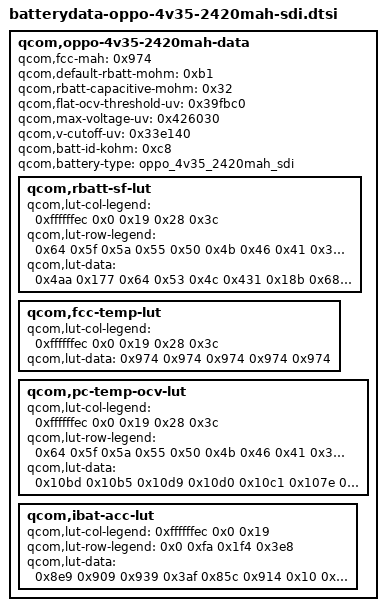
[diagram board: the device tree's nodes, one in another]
/* Copyright (c) 2020, The Linux Foundation. All rights reserved.
*  Copyright (c) 2020, the_shahnawaz_sheikh (sheikhshahnawaz41299).
*
* This program is free software; you can redistribute it and/or modify
* it under the terms of the GNU General Public License version 2 and
* only version 2 as published by the Free Software Foundation.
*
* This program is distributed in the hope that it will be useful,
* but WITHOUT ANY WARRANTY; without even the implied warranty of
* MERCHANTABILITY or FITNESS FOR A PARTICULAR PURPOSE.  See the
* GNU General Public License for more details.
*/

		qcom,oppo-4v35-2420mah-data {
			qcom,fcc-mah = <0x974>;
			qcom,default-rbatt-mohm = <0xb1>;
			qcom,rbatt-capacitive-mohm = <0x32>;
			qcom,flat-ocv-threshold-uv = <0x39fbc0>;
			qcom,max-voltage-uv = <0x426030>;
			qcom,v-cutoff-uv = <0x33e140>;
			qcom,batt-id-kohm = <0xc8>;
			qcom,battery-type = "oppo_4v35_2420mah_sdi";

			qcom,rbatt-sf-lut {
				qcom,lut-col-legend = <0xffffffec 0x0 0x19 0x28 0x3c>;
				qcom,lut-row-legend = <0x64 0x5f 0x5a 0x55 0x50 0x4b 0x46 0x41 0x3c 0x37 0x32 0x2d 0x28 0x23 0x1e 0x19 0x14 0x10 0xd 0xb 0xa 0x9 0x8 0x7 0x6 0x5 0x4 0x3 0x2 0x1 0x0>;
				qcom,lut-data = <0x4aa 0x177 0x64 0x53 0x4c 0x431 0x18b 0x68 0x56 0x4e 0x3df 0x172 0x6a 0x53 0x4c 0x3ac 0x172 0x6c 0x55 0x50 0x38d 0x15c 0x65 0x57 0x50 0x355 0x155 0x6e 0x5e 0x52 0x346 0x14d 0x6b 0x5c 0x59 0x346 0x139 0x73 0x63 0x5c 0x344 0x125 0x6a 0x52 0x4f 0x346 0x124 0x62 0x4e 0x4c 0x34f 0x139 0x63 0x55 0x50 0x363 0x124 0x60 0x53 0x50 0x373 0x123 0x60 0x59 0x52 0x38b 0x136 0x63 0x5a 0x53 0x3b0 0x14d 0x62 0x56 0x52 0x3de 0x155 0x63 0x53 0x4f 0x416 0x162 0x66 0x57 0x4f 0x439 0x180 0x69 0x53 0x50 0x46f 0x18f 0x6c 0x55 0x50 0x48b 0x1a1 0x65 0x57 0x53 0x4a2 0x1b2 0x63 0x56 0x50 0x4b4 0x1b7 0x64 0x59 0x50 0x4dd 0x1d4 0x65 0x59 0x56 0x4f4 0x1cc 0x69 0x5c 0x53 0x511 0x1ee 0x6b 0x59 0x52 0x526 0x1e2 0x6c 0x59 0x55 0x541 0x1f0 0x6f 0x59 0x57 0x55b 0x1f6 0x72 0x5c 0x5a 0x59b 0x218 0x77 0x74 0x6e 0x69d 0x261 0xb6 0x2c4 0x1d0 0x7b7 0x333 0x14b 0x338 0x226>;
			};

			qcom,fcc-temp-lut {
				qcom,lut-col-legend = <0xffffffec 0x0 0x19 0x28 0x3c>;
				qcom,lut-data = <0x974 0x974 0x974 0x974 0x974>;
			};

			qcom,pc-temp-ocv-lut {
				qcom,lut-col-legend = <0xffffffec 0x0 0x19 0x28 0x3c>;
				qcom,lut-row-legend = <0x64 0x5f 0x5a 0x55 0x50 0x4b 0x46 0x41 0x3c 0x37 0x32 0x2d 0x28 0x23 0x1e 0x19 0x14 0x10 0xd 0xb 0xa 0x9 0x8 0x7 0x6 0x5 0x4 0x3 0x2 0x1 0x0>;
				qcom,lut-data = <0x10bd 0x10b5 0x10d9 0x10d0 0x10c1 0x107e 0x107d 0x109e 0x1097 0x1089 0x1049 0x1047 0x1068 0x105f 0x1051 0x101c 0x101e 0x1035 0x102d 0x101e 0xfec 0xff1 0x1000 0xff7 0xff4 0xfa6 0xfbb 0xfd9 0xfd5 0xfc5 0xf63 0xf7c 0xf98 0xfa0 0xf99 0xf45 0xf61 0xf80 0xf7d 0xf73 0xf2d 0xf36 0xf4d 0xf43 0xf3f 0xf13 0xf0f 0xf1c 0xf1e 0xf16 0xefa 0xef5 0xf01 0xf01 0xf01 0xee5 0xee2 0xeeb 0xef1 0xeeb 0xed4 0xed3 0xed9 0xee1 0xedc 0xecb 0xec7 0xecc 0xed0 0xecc 0xec1 0xeb9 0xebd 0xeba 0xeaf 0xeb5 0xeb1 0xeac 0xea6 0xe9a 0xea3 0xe9f 0xe9a 0xe98 0xe83 0xe93 0xe8b 0xe82 0xe7c 0xe6e 0xe87 0xe72 0xe6f 0xe6a 0xe5c 0xe82 0xe6e 0xe67 0xe69 0xe5c 0xe7f 0xe6c 0xe66 0xe67 0xe59 0xe7d 0xe6c 0xe65 0xe67 0xe58 0xe76 0xe6a 0xe64 0xe62 0xe54 0xe71 0xe68 0xe63 0xe5d 0xe4d 0xe69 0xe66 0xe56 0xe4a 0xe37 0xe5b 0xe57 0xe3b 0xe24 0xe15 0xe47 0xe39 0xe14 0xdf8 0xdea 0xe2c 0xe12 0xde1 0xdc0 0xdb2 0xdd2 0xd9e 0xda0 0xd06 0xd01 0xd34 0xd38 0xca1 0xc47 0xc4f 0xbb8 0xbb8 0xbb8 0xbb8 0xbb8>;
			};

			qcom,ibat-acc-lut {
				qcom,lut-col-legend = <0xffffffec 0x0 0x19>;
				qcom,lut-row-legend = <0x0 0xfa 0x1f4 0x3e8>;
				qcom,lut-data = <0x8e9 0x909 0x939 0x3af 0x85c 0x914 0x10 0x577 0x8f4 0x0 0x566 0x8a9>;
			};
		};

